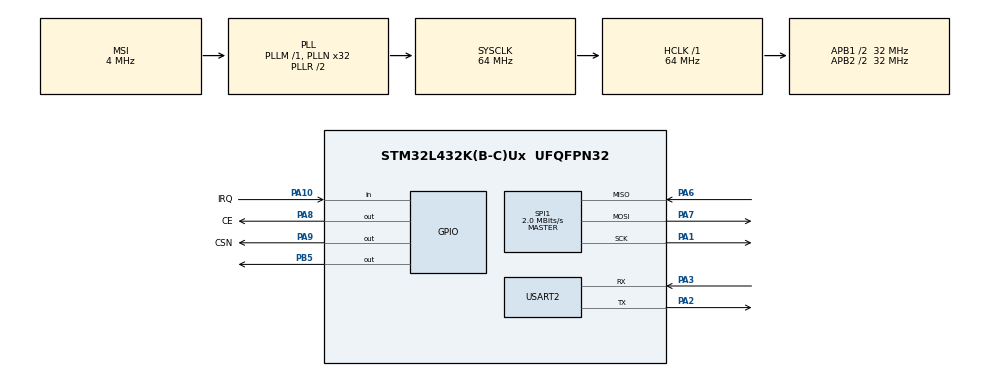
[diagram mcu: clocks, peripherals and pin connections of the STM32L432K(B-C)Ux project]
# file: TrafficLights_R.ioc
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Mcu.Family=STM32L4
Mcu.Name=STM32L432K(B-C)Ux
Mcu.Package=UFQFPN32
NVIC.PriorityGroup=NVIC_PRIORITYGROUP_4
PA0.Mode=HSE-External-Clock-Source-for-LittleOrca
PA0.Signal=RCC_CK_IN
PA1.Mode=Full_Duplex_Master
PA1.Signal=SPI1_SCK
PA10.GPIO_Label=IRQ
PA10.Signal=GPIO_Input
PA2.Mode=Asynchronous
PA2.Signal=USART2_TX
PA3.Mode=Asynchronous
PA3.Signal=USART2_RX
PA6.Mode=Full_Duplex_Master
PA6.Signal=SPI1_MISO
PA7.Mode=Full_Duplex_Master
PA7.Signal=SPI1_MOSI
PA8.GPIO_Label=CE
PA8.Signal=GPIO_Output
PA9.GPIO_Label=CSN
PA9.Signal=GPIO_Output
PB5.Signal=GPIO_Output
ProjectManager.HeapSize=0x200
ProjectManager.StackSize=0x400
ProjectManager.TargetToolchain=SW4STM32
RCC.ADCFreq_Value=48000000
RCC.AHBFreq_Value=64000000
RCC.APB1CLKDivider=RCC_HCLK_DIV2
RCC.APB1Freq_Value=32000000
RCC.APB1TimFreq_Value=64000000
RCC.APB2CLKDivider=RCC_HCLK_DIV2
RCC.APB2Freq_Value=32000000
RCC.APB2TimFreq_Value=64000000
RCC.CortexFreq_Value=64000000
RCC.HCLKFreq_Value=64000000
RCC.HSE_VALUE=8000000
RCC.HSI48_VALUE=48000000
RCC.HSI_VALUE=16000000
RCC.LSE_VALUE=32768
RCC.MSI_VALUE=4000000
RCC.PLLN=32
RCC.PLLSAI1N=24
RCC.SYSCLKFreq_VALUE=64000000
RCC.SYSCLKSource=RCC_SYSCLKSOURCE_PLLCLK
RCC.USBFreq_Value=48000000
RCC.VCOOutputFreq_Value=128000000
SPI1.BaudRatePrescaler=SPI_BAUDRATEPRESCALER_16
SPI1.CalculateBaudRate=2.0 MBits/s
SPI1.Direction=SPI_DIRECTION_2LINES
SPI1.Mode=SPI_MODE_MASTER
SPI1.VirtualType=VM_MASTER
USART2.VirtualMode-Asynchronous=VM_ASYNC
board=custom

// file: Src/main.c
/* USER CODE BEGIN Header */
/**
  ******************************************************************************
  * @file           : main.c
  * @brief          : Main program body
  ******************************************************************************
  * @attention
  *
  * <h2><center>&copy; Copyright (c) 2019 STMicroelectronics.
  * All rights reserved.</center></h2>
  *
  * This software component is licensed by ST under BSD 3-Clause license,
  * the "License"; You may not use this file except in compliance with the
  * License. You may obtain a copy of the License at:
  *                        opensource.org/licenses/BSD-3-Clause
  *
  ******************************************************************************
  */
/* USER CODE END Header */

#include "main.h"

/* USER CODE BEGIN Includes */
#include "NRF24.h"
#include <string.h>
/* USER CODE END Includes */

SPI_HandleTypeDef hspi1;

UART_HandleTypeDef huart2;

/* USER CODE BEGIN PV */
char str1[150]={0};
uint8_t buf1[20] = {0};
/* USER CODE END PV */

void SystemClock_Config(void);
static void MX_GPIO_Init(void);
static void MX_SPI1_Init(void);
static void MX_USART2_UART_Init(void);

int main(void)
{

  /* MCU Configuration--------------------------------------------------------*/

  /* Reset of all peripherals, Initializes the Flash interface and the Systick. */
  HAL_Init();

  /* Configure the system clock */
  SystemClock_Config();

  /* Initialize all configured peripherals */
  MX_GPIO_Init();
  MX_SPI1_Init();
  MX_USART2_UART_Init();
  /* USER CODE BEGIN 2 */
    NRF24_ini();
  /* USER CODE END 2 */

  /* Infinite loop */
    while (1) {
    NRF24L01_Receive();
    }
}

void SystemClock_Config(void)
{
  RCC_OscInitTypeDef RCC_OscInitStruct = {0};
  RCC_ClkInitTypeDef RCC_ClkInitStruct = {0};
  RCC_PeriphCLKInitTypeDef PeriphClkInit = {0};

  /** Initializes the CPU, AHB and APB busses clocks
  */
  RCC_OscInitStruct.OscillatorType = RCC_OSCILLATORTYPE_MSI;
  RCC_OscInitStruct.MSIState = RCC_MSI_ON;
  RCC_OscInitStruct.MSICalibrationValue = 0;
  RCC_OscInitStruct.MSIClockRange = RCC_MSIRANGE_6;
  RCC_OscInitStruct.PLL.PLLState = RCC_PLL_ON;
  RCC_OscInitStruct.PLL.PLLSource = RCC_PLLSOURCE_MSI;
  RCC_OscInitStruct.PLL.PLLM = 1;
  RCC_OscInitStruct.PLL.PLLN = 32;
  RCC_OscInitStruct.PLL.PLLP = RCC_PLLP_DIV7;
  RCC_OscInitStruct.PLL.PLLQ = RCC_PLLQ_DIV2;
  RCC_OscInitStruct.PLL.PLLR = RCC_PLLR_DIV2;
  if (HAL_RCC_OscConfig(&RCC_OscInitStruct) != HAL_OK)
  {
    Error_Handler();
  }
  /** Initializes the CPU, AHB and APB busses clocks
  */
  RCC_ClkInitStruct.ClockType = RCC_CLOCKTYPE_HCLK|RCC_CLOCKTYPE_SYSCLK
                              |RCC_CLOCKTYPE_PCLK1|RCC_CLOCKTYPE_PCLK2;
  RCC_ClkInitStruct.SYSCLKSource = RCC_SYSCLKSOURCE_PLLCLK;
  RCC_ClkInitStruct.AHBCLKDivider = RCC_SYSCLK_DIV1;
  RCC_ClkInitStruct.APB1CLKDivider = RCC_HCLK_DIV2;
  RCC_ClkInitStruct.APB2CLKDivider = RCC_HCLK_DIV2;

  if (HAL_RCC_ClockConfig(&RCC_ClkInitStruct, FLASH_LATENCY_3) != HAL_OK)
  {
    Error_Handler();
  }
  PeriphClkInit.PeriphClockSelection = RCC_PERIPHCLK_USART2;
  PeriphClkInit.Usart2ClockSelection = RCC_USART2CLKSOURCE_PCLK1;
  if (HAL_RCCEx_PeriphCLKConfig(&PeriphClkInit) != HAL_OK)
  {
    Error_Handler();
  }
  /** Configure the main internal regulator output voltage
  */
  if (HAL_PWREx_ControlVoltageScaling(PWR_REGULATOR_VOLTAGE_SCALE1) != HAL_OK)
  {
    Error_Handler();
  }
}

static void MX_SPI1_Init(void)
{

  /* SPI1 parameter configuration*/
  hspi1.Instance = SPI1;
  hspi1.Init.Mode = SPI_MODE_MASTER;
  hspi1.Init.Direction = SPI_DIRECTION_2LINES;
  hspi1.Init.DataSize = SPI_DATASIZE_4BIT;
  hspi1.Init.CLKPolarity = SPI_POLARITY_LOW;
  hspi1.Init.CLKPhase = SPI_PHASE_1EDGE;
  hspi1.Init.NSS = SPI_NSS_SOFT;
  hspi1.Init.BaudRatePrescaler = SPI_BAUDRATEPRESCALER_16;
  hspi1.Init.FirstBit = SPI_FIRSTBIT_MSB;
  hspi1.Init.TIMode = SPI_TIMODE_DISABLE;
  hspi1.Init.CRCCalculation = SPI_CRCCALCULATION_DISABLE;
  hspi1.Init.CRCPolynomial = 7;
  hspi1.Init.CRCLength = SPI_CRC_LENGTH_DATASIZE;
  hspi1.Init.NSSPMode = SPI_NSS_PULSE_ENABLE;
  if (HAL_SPI_Init(&hspi1) != HAL_OK)
  {
    Error_Handler();
  }

}

static void MX_USART2_UART_Init(void)
{

  huart2.Instance = USART2;
  huart2.Init.BaudRate = 115200;
  huart2.Init.WordLength = UART_WORDLENGTH_8B;
  huart2.Init.StopBits = UART_STOPBITS_1;
  huart2.Init.Parity = UART_PARITY_NONE;
  huart2.Init.Mode = UART_MODE_TX_RX;
  huart2.Init.HwFlowCtl = UART_HWCONTROL_NONE;
  huart2.Init.OverSampling = UART_OVERSAMPLING_16;
  huart2.Init.OneBitSampling = UART_ONE_BIT_SAMPLE_DISABLE;
  huart2.AdvancedInit.AdvFeatureInit = UART_ADVFEATURE_NO_INIT;
  if (HAL_UART_Init(&huart2) != HAL_OK)
  {
    Error_Handler();
  }

}

static void MX_GPIO_Init(void)
{
  GPIO_InitTypeDef GPIO_InitStruct = {0};

  /* GPIO Ports Clock Enable */
  __HAL_RCC_GPIOA_CLK_ENABLE();
  __HAL_RCC_GPIOB_CLK_ENABLE();

  /*Configure GPIO pin Output Level */
  HAL_GPIO_WritePin(GPIOA, CE_Pin|CSN_Pin, GPIO_PIN_RESET);

  /*Configure GPIO pin Output Level */
  HAL_GPIO_WritePin(GPIOB, GPIO_PIN_5, GPIO_PIN_RESET);

  /*Configure GPIO pins : CE_Pin CSN_Pin */
  GPIO_InitStruct.Pin = CE_Pin|CSN_Pin;
  GPIO_InitStruct.Mode = GPIO_MODE_OUTPUT_PP;
  GPIO_InitStruct.Pull = GPIO_NOPULL;
  GPIO_InitStruct.Speed = GPIO_SPEED_FREQ_LOW;
  HAL_GPIO_Init(GPIOA, &GPIO_InitStruct);

  /*Configure GPIO pin : IRQ_Pin */
  GPIO_InitStruct.Pin = IRQ_Pin;
  GPIO_InitStruct.Mode = GPIO_MODE_INPUT;
  GPIO_InitStruct.Pull = GPIO_NOPULL;
  HAL_GPIO_Init(IRQ_GPIO_Port, &GPIO_InitStruct);

  /*Configure GPIO pin : PB5 */
  GPIO_InitStruct.Pin = GPIO_PIN_5;
  GPIO_InitStruct.Mode = GPIO_MODE_OUTPUT_PP;
  GPIO_InitStruct.Pull = GPIO_NOPULL;
  GPIO_InitStruct.Speed = GPIO_SPEED_FREQ_LOW;
  HAL_GPIO_Init(GPIOB, &GPIO_InitStruct);

}

void Error_Handler(void)
{
}

/************************ (C) COPYRIGHT STMicroelectronics *****END OF FILE****/
